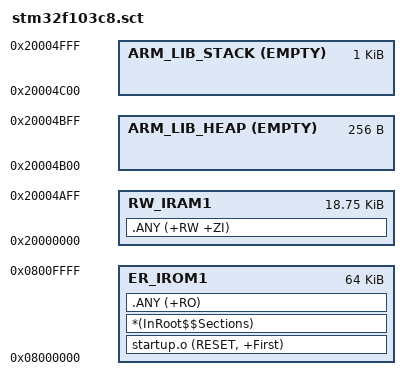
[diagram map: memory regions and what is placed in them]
; Keil ARM Compiler 6, full C library. Reserve 256B heap and 1KB stack.
LR_IROM1 0x08000000 0x00010000 {
  ER_IROM1 0x08000000 0x00010000 {
    startup.o (RESET, +First)
    *(InRoot$$Sections)
    .ANY (+RO)
  }
  RW_IRAM1 0x20000000 0x00004B00 {
    .ANY (+RW +ZI)
  }
  ARM_LIB_HEAP 0x20004B00 EMPTY 0x100 { }
  ARM_LIB_STACK 0x20005000 EMPTY -0x400 { }
}
